# RX64M_GPT_Pilot register map
File version: 1.0
RX64M_GPT_Pilot peripheral registers generated from iodefine.h (pilot).
Registers are 16-bit, read-write, reset 0xFFFF unless marked. A register's access mark holds for its fields unless they carry their own. Offsets are from the block's base; lines under a group give offsets from that group; [hi:lo] are bit positions; {n}, {i} and the like mark numbered series; 'fields as' and 'values as' point back to an identical list; <NAME> marks a mode.

## Memory map
0x000C2000 GPT size 0x1A
0x000C2100 GPT0 size 0x44
0x000C2180 GPT1 size 0x44
0x000C2200 GPT2 size 0x44
0x000C2280 GPT3 size 0x44

## GPT
Base 0x000C2000
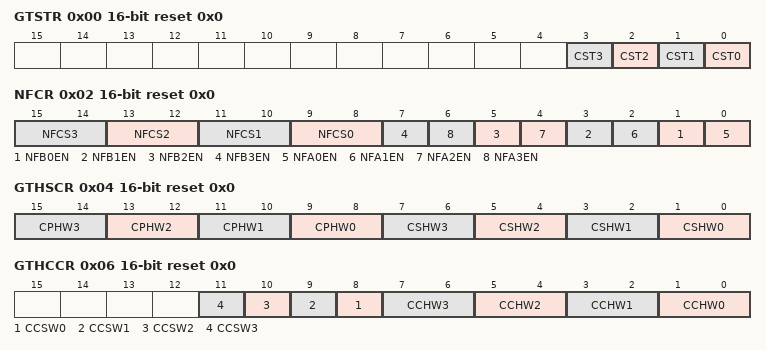
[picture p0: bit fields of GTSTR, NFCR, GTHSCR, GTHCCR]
0x00 GTSTR reset 0x0
  [n] CST{n} (n=0..3)
0x02 NFCR reset 0x0
  [2n+9:2n+8] NFCS{n} (n=0..3), [2n+1] NFB{n}EN (n=0..3), [2n] NFA{n}EN (n=0..3)
0x04 GTHSCR reset 0x0
  [2n+9:2n+8] CPHW{n} (n=0..3), [2n+1:2n] CSHW{n} (n=0..3)
0x06 GTHCCR reset 0x0
  [n+8] CCSW{n} (n=0..3), [2n+1:2n] CCHW{n} (n=0..3)
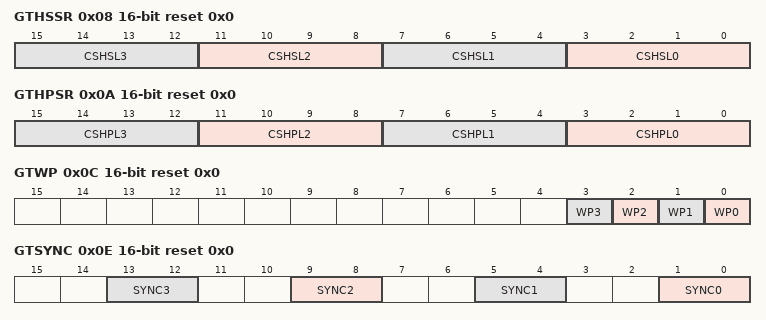
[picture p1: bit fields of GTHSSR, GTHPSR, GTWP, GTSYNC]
0x08 GTHSSR reset 0x0
  [4n+3:4n] CSHSL{n} (n=0..3)
0x0A GTHPSR reset 0x0
  [4n+3:4n] CSHPL{n} (n=0..3)
0x0C GTWP reset 0x0
  [n] WP{n} (n=0..3)
0x0E GTSYNC reset 0x0
  [4n+1:4n] SYNC{n} (n=0..3)
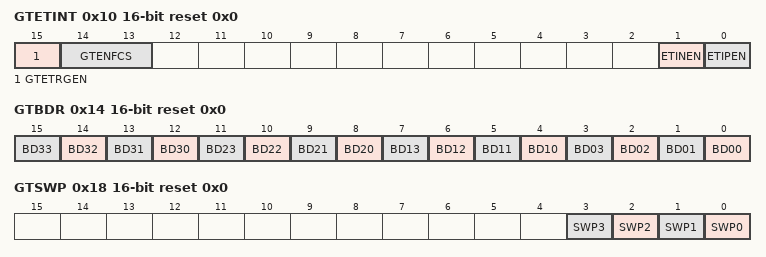
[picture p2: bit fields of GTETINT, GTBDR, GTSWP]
0x10 GTETINT reset 0x0
  [15] GTETRGEN, [14:13] GTENFCS, [1] ETINEN, [0] ETIPEN
0x14 GTBDR reset 0x0
  [n-18] BD{n} (n=30..33), [n-12] BD{n} (n=20..23), [n-6] BD{n} (n=10..13), [n] BD{n:02} (n=0..3)
0x18 GTSWP reset 0x0
  [n] SWP{n} (n=0..3)

## GPT0
Base 0x000C2100
Same registers: GPT1 0x000C2180, GPT2 0x000C2200, GPT3 0x000C2280
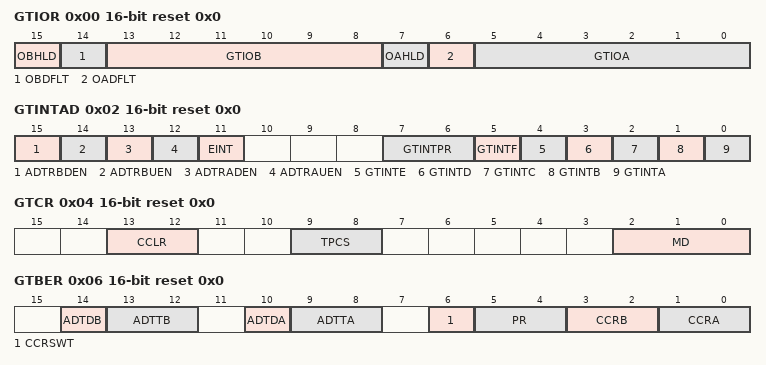
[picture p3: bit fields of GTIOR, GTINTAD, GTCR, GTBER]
0x00 GTIOR reset 0x0
  [15] OBHLD, [14] OBDFLT, [13:8] GTIOB, [7] OAHLD, [6] OADFLT, [5:0] GTIOA
0x02 GTINTAD reset 0x0
  [15] ADTRBDEN, [14] ADTRBUEN, [13] ADTRADEN, [12] ADTRAUEN, [11] EINT, [7:6] GTINTPR, [5] GTINTF, [4] GTINTE, [3] GTINTD, [2] GTINTC, [1] GTINTB, [0] GTINTA
0x04 GTCR reset 0x0
  [13:12] CCLR, [9:8] TPCS, [2:0] MD
0x06 GTBER reset 0x0
  [14] ADTDB, [13:12] ADTTB, [10] ADTDA, [9:8] ADTTA, [6] CCRSWT, [5:4] PR, [3:2] CCRB, [1:0] CCRA
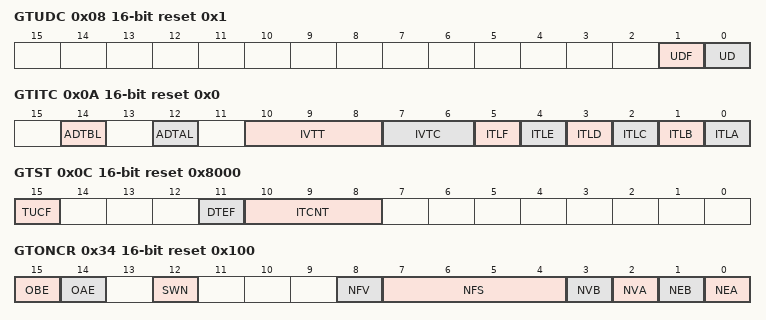
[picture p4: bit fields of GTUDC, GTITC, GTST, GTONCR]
0x08 GTUDC reset 0x1
  [1] UDF, [0] UD
0x0A GTITC reset 0x0
  [14] ADTBL, [12] ADTAL, [10:8] IVTT, [7:6] IVTC, [5] ITLF, [4] ITLE, [3] ITLD, [2] ITLC, [1] ITLB, [0] ITLA
0x0C GTST reset 0x8000
  [15] TUCF, [11] DTEF, [10:8] ITCNT
0x0E GTCNT reset 0x0
0x10 GTCCRA
0x12 GTCCRB
0x14 GTCCRC
0x16 GTCCRD
0x18 GTCCRE
0x1A GTCCRF
0x1C GTPR
0x1E GTPBR
0x20 GTPDBR
0x24 GTADTRA
0x26 GTADTBRA
0x28 GTADTDBRA
0x2C GTADTRB
0x2E GTADTBRB
0x30 GTADTDBRB
0x34 GTONCR reset 0x100
  [15] OBE, [14] OAE, [12] SWN, [8] NFV, [7:4] NFS, [3] NVB, [2] NVA, [1] NEB, [0] NEA
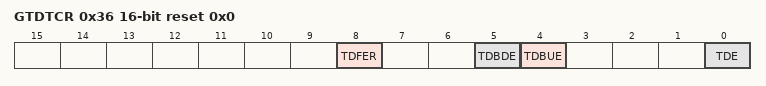
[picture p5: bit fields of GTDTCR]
0x36 GTDTCR reset 0x0
  [8] TDFER, [5] TDBDE, [4] TDBUE, [0] TDE
0x38 GTDVU
0x3A GTDVD
0x3C GTDBU
0x3E GTDBD
0x40 GTSOS ro reset 0x0
  [1:0] SOS
0x42 GTSOTR reset 0x0
  [0] SOTR
